# MCXC444 register map
Vendor: NXP Semiconductors; Series: MCX; File version: 1.6
CPU: CM0PLUS r0p0, little endian, no MPU, no FPU, VTOR, 2 interrupt priority bits
Registers are 32-bit, read-write, reset 0x0 unless marked. A register's access mark holds for its fields unless they carry their own. Offsets are from the block's base; [hi:lo] are bit positions.

## LPTMR0 — Low Power Timer
Base 0x40040000; register names take the prefix LPTMR0_
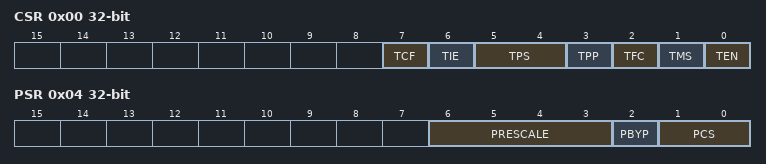
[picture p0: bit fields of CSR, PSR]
0x00 CSR — Low Power Timer Control Status Register
  [7] TCF — Timer Compare Flag
    0=b0 (The value of CNR is not equal to CMR and increments.); 1=b1 (The value of CNR is equal to CMR and increments.)
  [6] TIE — Timer Interrupt Enable
    0=b0 (Timer interrupt disabled.); 1=b1 (Timer interrupt enabled.)
  [5:4] TPS — Timer Pin Select
    0=b00 (Pulse counter input 0 is selected.); 1=b01 (Pulse counter input 1 is selected.); 2=b10 (Pulse counter input 2 is selected.); 3=b11 (Pulse counter input 3 is selected.)
  [3] TPP — Timer Pin Polarity
    0=b0 (Pulse Counter input source is active-high, and the CNR will increment on the rising-edge.); 1=b1 (Pulse Counter input source is active-low, and the CNR will increment on the falling-edge.)
  [2] TFC — Timer Free-Running Counter
    0=b0 (CNR is reset whenever TCF is set.); 1=b1 (CNR is reset on overflow.)
  [1] TMS — Timer Mode Select
    0=b0 (Time Counter mode.); 1=b1 (Pulse Counter mode.)
  [0] TEN — Timer Enable
    0=b0 (LPTMR is disabled and internal logic is reset.); 1=b1 (LPTMR is enabled.)
0x04 PSR — Low Power Timer Prescale Register
  [6:3] PRESCALE — Prescale Value
    0=b0000 (Prescaler divides the prescaler clock by 2; glitch filter does not support this configuration.); 1=b0001 (Prescaler divides the prescaler clock by 4; glitch filter recognizes change on input pin after 2 rising clock edges.); 2=b0010 (Prescaler divides the prescaler clock by 8; glitch filter recognizes change on input pin after 4 rising clock edges.); 3=b0011 (Prescaler divides the prescaler clock by 16; glitch filter recognizes change on input pin after 8 rising clock edges.); 4=b0100 (Prescaler divides the prescaler clock by 32; glitch filter recognizes change on input pin after 16 rising clock edges.); 5=b0101 (Prescaler divides the prescaler clock by 64; glitch filter recognizes change on input pin after 32 rising clock edges.); 6=b0110 (Prescaler divides the prescaler clock by 128; glitch filter recognizes change on input pin after 64 rising clock edges.); 7=b0111 (Prescaler divides the prescaler clock by 256; glitch filter recognizes change on input pin after 128 rising clock edges.); 8=b1000 (Prescaler divides the prescaler clock by 512; glitch filter recognizes change on input pin after 256 rising clock edges.); 9=b1001 (Prescaler divides the prescaler clock by 1024; glitch filter recognizes change on input pin after 512 rising clock edges.); 10=b1010 (Prescaler divides the prescaler clock by 2048; glitch filter recognizes change on input pin after 1024 rising clock edges.); 11=b1011 (Prescaler divides the prescaler clock by 4096; glitch filter recognizes change on input pin after 2048 rising clock edges.); 12=b1100 (Prescaler divides the prescaler clock by 8192; glitch filter recognizes change on input pin after 4096 rising clock edges.); 13=b1101 (Prescaler divides the prescaler clock by 16,384; glitch filter recognizes change on input pin after 8192 rising clock edges.); 14=b1110 (Prescaler divides the prescaler clock by 32,768; glitch filter recognizes change on input pin after 16,384 rising clock edges.); 15=b1111 (Prescaler divides the prescaler clock by 65,536; glitch filter recognizes change on input pin after 32,768 rising clock edges.)
  [2] PBYP — Prescaler Bypass
    0=b0 (Prescaler/glitch filter is enabled.); 1=b1 (Prescaler/glitch filter is bypassed.)
  [1:0] PCS — Prescaler Clock Select
    0=b00 (Prescaler/glitch filter clock 0 selected.); 1=b01 (Prescaler/glitch filter clock 1 selected.); 2=b10 (Prescaler/glitch filter clock 2 selected.); 3=b11 (Prescaler/glitch filter clock 3 selected.)
0x08 CMR — Low Power Timer Compare Register
  [15:0] COMPARE — Compare Value
0x0C CNR — Low Power Timer Counter Register
  [15:0] COUNTER — Counter Value
